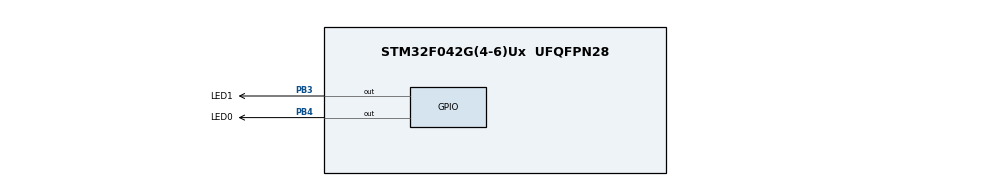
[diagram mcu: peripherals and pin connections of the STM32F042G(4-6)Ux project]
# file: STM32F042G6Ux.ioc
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Mcu.Family=STM32F0
Mcu.Name=STM32F042G(4-6)Ux
Mcu.Package=UFQFPN28
PB3.GPIO_Label=LED1
PB3.Signal=GPIO_Output
PB4.GPIO_Label=LED0
PB4.Signal=GPIO_Output
ProjectManager.HeapSize=0x200
ProjectManager.StackSize=0x400
ProjectManager.TargetToolchain=Makefile
RCC.AHBFreq_Value=48000000
RCC.APB1Freq_Value=48000000
RCC.APB1TimFreq_Value=48000000
RCC.HCLKFreq_Value=48000000
RCC.SYSCLKFreq_VALUE=48000000
RCC.SYSCLKSource=RCC_SYSCLKSOURCE_HSI48
board=custom

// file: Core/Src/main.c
/* USER CODE BEGIN Header */
/**
 ******************************************************************************
 * @file           : main.c
 * @brief          : Main program body
 ******************************************************************************
 * @attention
 *
 * Copyright (c) 2024 STMicroelectronics.
 * All rights reserved.
 *
 * This software is licensed under terms that can be found in the LICENSE file
 * in the root directory of this software component.
 * If no LICENSE file comes with this software, it is provided AS-IS.
 *
 ******************************************************************************
 */
/* USER CODE END Header */
#include "main.h"
#include "gpio.h"

/* USER CODE BEGIN Includes */
#include <stdint.h>
/* USER CODE END Includes */

void SystemClock_Config(void);

/* USER CODE BEGIN 0 */
uint8_t count = 0;
/* USER CODE END 0 */

int main(void)
{

    /* MCU
     * Configuration--------------------------------------------------------*/

    /* Reset of all peripherals, Initializes the Flash interface and the
     * Systick. */
    LL_APB1_GRP2_EnableClock(LL_APB1_GRP2_PERIPH_SYSCFG);
    LL_APB1_GRP1_EnableClock(LL_APB1_GRP1_PERIPH_PWR);

    /* SysTick_IRQn interrupt configuration */
    NVIC_SetPriority(SysTick_IRQn, 3);

    /* Configure the system clock */
    SystemClock_Config();

    /* Initialize all configured peripherals */
    MX_GPIO_Init();

    /* Infinite loop */
    /* USER CODE BEGIN WHILE */
    LL_GPIO_ResetOutputPin(LED0_GPIO_Port, LED0_Pin);
    LL_GPIO_ResetOutputPin(LED1_GPIO_Port, LED1_Pin);
    while (1)
    {
        /* USER CODE END WHILE */

        /* USER CODE BEGIN 3 */
        count++;
        LL_mDelay(500);
        LL_GPIO_SetOutputPin(LED1_GPIO_Port, LED1_Pin);
        LL_mDelay(500);
        LL_GPIO_ResetOutputPin(LED1_GPIO_Port, LED1_Pin);
    }
    /* USER CODE END 3 */
}

void SystemClock_Config(void)
{
    LL_FLASH_SetLatency(LL_FLASH_LATENCY_1);
    while (LL_FLASH_GetLatency() != LL_FLASH_LATENCY_1)
    {
    }
    LL_RCC_HSI48_Enable();

    /* Wait till HSI48 is ready */
    while (LL_RCC_HSI48_IsReady() != 1)
    {
    }
    LL_RCC_SetAHBPrescaler(LL_RCC_SYSCLK_DIV_1);
    LL_RCC_SetAPB1Prescaler(LL_RCC_APB1_DIV_1);
    LL_RCC_SetSysClkSource(LL_RCC_SYS_CLKSOURCE_HSI48);

    /* Wait till System clock is ready */
    while (LL_RCC_GetSysClkSource() != LL_RCC_SYS_CLKSOURCE_STATUS_HSI48)
    {
    }
    LL_Init1msTick(48000000);
    LL_SetSystemCoreClock(48000000);
}

void Error_Handler(void)
{
    /* USER CODE BEGIN Error_Handler_Debug */
    /* User can add his own implementation to report the HAL error return state
     */
    __disable_irq();
    while (1)
    {
    }
    /* USER CODE END Error_Handler_Debug */
}

#ifdef USE_FULL_ASSERT
/**
 * @brief  Reports the name of the source file and the source line number
 *         where the assert_param error has occurred.
 * @param  file: pointer to the source file name
 * @param  line: assert_param error line source number
 * @retval None
 */
void assert_failed(uint8_t *file, uint32_t line)
{
    /* USER CODE BEGIN 6 */
    /* User can add his own implementation to report the file name and line
       number, ex: printf("Wrong parameters value: file %s on line %d\r\n",
       file, line) */
    /* USER CODE END 6 */
}
#endif /* USE_FULL_ASSERT */
